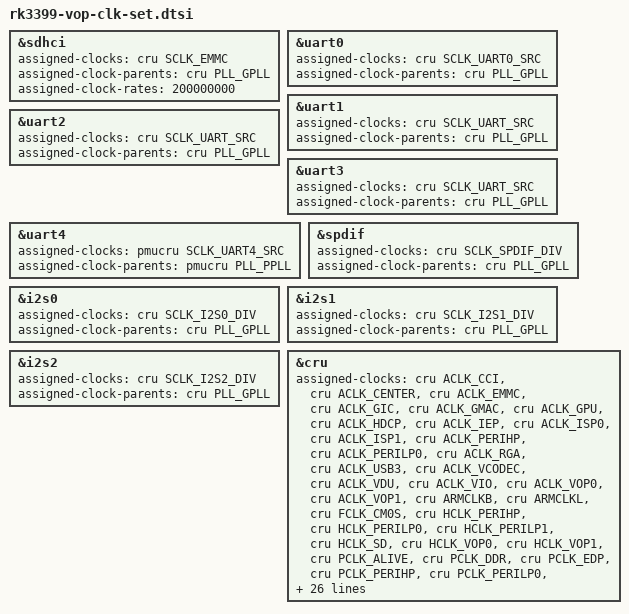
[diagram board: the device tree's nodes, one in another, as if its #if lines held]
/*
 * Copyright (c) 2016 Fuzhou Rockchip Electronics Co., Ltd
 *
 * This file is dual-licensed: you can use it either under the terms
 * of the GPL or the X11 license, at your option. Note that this dual
 * licensing only applies to this file, and not this project as a
 * whole.
 *
 *  a) This file is free software; you can redistribute it and/or
 *     modify it under the terms of the GNU General Public License as
 *     published by the Free Software Foundation; either version 2 of the
 *     License, or (at your option) any later version.
 *
 *     This file is distributed in the hope that it will be useful,
 *     but WITHOUT ANY WARRANTY; without even the implied warranty of
 *     MERCHANTABILITY or FITNESS FOR A PARTICULAR PURPOSE.  See the
 *     GNU General Public License for more details.
 *
 * Or, alternatively,
 *
 *  b) Permission is hereby granted, free of charge, to any person
 *     obtaining a copy of this software and associated documentation
 *     files (the "Software"), to deal in the Software without
 *     restriction, including without limitation the rights to use,
 *     copy, modify, merge, publish, distribute, sublicense, and/or
 *     sell copies of the Software, and to permit persons to whom the
 *     Software is furnished to do so, subject to the following
 *     conditions:
 *
 *     The above copyright notice and this permission notice shall be
 *     included in all copies or substantial portions of the Software.
 *
 *     THE SOFTWARE IS PROVIDED "AS IS", WITHOUT WARRANTY OF ANY KIND,
 *     EXPRESS OR IMPLIED, INCLUDING BUT NOT LIMITED TO THE WARRANTIES
 *     OF MERCHANTABILITY, FITNESS FOR A PARTICULAR PURPOSE AND
 *     NONINFRINGEMENT. IN NO EVENT SHALL THE AUTHORS OR COPYRIGHT
 *     HOLDERS BE LIABLE FOR ANY CLAIM, DAMAGES OR OTHER LIABILITY,
 *     WHETHER IN AN ACTION OF CONTRACT, TORT OR OTHERWISE, ARISING
 *     FROM, OUT OF OR IN CONNECTION WITH THE SOFTWARE OR THE USE OR
 *     OTHER DEALINGS IN THE SOFTWARE.
 */

/*
 * This define is for support double show any dclk frequency.
 * dclk_vop will have a exclusive pll as parent.
 * set dclk_vop will change the pll rate as well.
 */

#ifdef RK3399_TWO_PLL_FOR_VOP

&sdhci {
		assigned-clocks = <&cru SCLK_EMMC>;
		assigned-clock-parents = <&cru PLL_GPLL>;
		assigned-clock-rates = <200000000>;
};

&uart0 {
		assigned-clocks = <&cru SCLK_UART0_SRC>;
		assigned-clock-parents = <&cru PLL_GPLL>;
};

&uart1 {
		assigned-clocks = <&cru SCLK_UART_SRC>;
		assigned-clock-parents = <&cru PLL_GPLL>;
};

&uart2 {
		assigned-clocks = <&cru SCLK_UART_SRC>;
		assigned-clock-parents = <&cru PLL_GPLL>;
};

&uart3 {
		assigned-clocks = <&cru SCLK_UART_SRC>;
		assigned-clock-parents = <&cru PLL_GPLL>;
};

&uart4 {
		assigned-clocks = <&pmucru SCLK_UART4_SRC>;
		assigned-clock-parents = <&pmucru PLL_PPLL>;
};

&spdif {
		assigned-clocks = <&cru SCLK_SPDIF_DIV>;
		assigned-clock-parents = <&cru PLL_GPLL>;
};

&i2s0{
		assigned-clocks = <&cru SCLK_I2S0_DIV>;
		assigned-clock-parents = <&cru PLL_GPLL>;
};

&i2s1 {
		assigned-clocks = <&cru SCLK_I2S1_DIV>;
		assigned-clock-parents = <&cru PLL_GPLL>;
};

&i2s2 {
		assigned-clocks = <&cru SCLK_I2S2_DIV>;
		assigned-clock-parents = <&cru PLL_GPLL>;
};

/* Rockchip had a bunch of duplicate clocks with different rates defined.
 * I have removed the duplicates, using only the one that was assigned last, and put them in alphabetical order.
 * Below are both values for the duplicated clocks for future reference:
 *   ACLK_CCI = 150000000, 600000000
 *   ACLK_CENTER = 100000000, 400000000
 *   ACLK_EMMC = 50000000, 100000000
 *   ACLK_GMAC = 100000000, 400000000
 *   ACLK_PERIHP = 150000000, 75000000
 *   ACLK_PERILP0 = 50000000, 300000000
 *   ACLK_USB3 = 150000000, 300000000
 *   FCLK_CM0S = 50000000, 300000000
 *   HCLK_PERILP1 = 100000000, 50000000
 *   HCLK_SD = 50000000, 200000000
 *   PCLK_ALIVE = 50000000, 100000000
 *   SCLK_CCI_TRACE = 75000000, 150000000
 *   SCLK_CS = 150000000, 75000000
 *   SCLK_RGA_CORE = 400000000
 *   SCLK_VDU_CA = 150000000, 300000000
 */
&cru {
		assigned-clocks =
			 <&cru ACLK_CCI>, <&cru ACLK_CENTER>,
			 <&cru ACLK_EMMC>, <&cru ACLK_GIC>,
			 <&cru ACLK_GMAC>, <&cru ACLK_GPU>,
			 <&cru ACLK_HDCP>, <&cru ACLK_IEP>,
			 <&cru ACLK_ISP0>, <&cru ACLK_ISP1>,
			 <&cru ACLK_PERIHP>, <&cru ACLK_PERILP0>,
			 <&cru ACLK_RGA>, <&cru ACLK_USB3>,
			 <&cru ACLK_VCODEC>, <&cru ACLK_VDU>,
			 <&cru ACLK_VIO>, <&cru ACLK_VOP0>,
			 <&cru ACLK_VOP1>, <&cru ARMCLKB>,
			 <&cru ARMCLKL>, <&cru FCLK_CM0S>,
			 <&cru HCLK_PERIHP>, <&cru HCLK_PERILP0>,
			 <&cru HCLK_PERILP1>, <&cru HCLK_SD>,
			 <&cru HCLK_VOP0>, <&cru HCLK_VOP1>,
			 <&cru PCLK_ALIVE>, <&cru PCLK_DDR>,
			 <&cru PCLK_EDP>, <&cru PCLK_PERIHP>,
			 <&cru PCLK_PERILP0>, <&cru PCLK_PERILP1>,
			 <&cru PLL_GPLL>, <&cru PLL_NPLL>,
			 <&cru SCLK_CCI_TRACE>, <&cru SCLK_CRYPTO0>,
			 <&cru SCLK_CRYPTO1>, <&cru SCLK_CS>,
			 <&cru SCLK_EMMC>, <&cru SCLK_I2C1>,
			 <&cru SCLK_I2C2>, <&cru SCLK_I2C3>,
			 <&cru SCLK_I2C5>, <&cru SCLK_I2C6>,
			 <&cru SCLK_I2C7>, <&cru SCLK_RGA_CORE>,
			 <&cru SCLK_SDMMC>, <&cru SCLK_SPI0>,
			 <&cru SCLK_SPI1>, <&cru SCLK_SPI2>,
			 <&cru SCLK_SPI4>, <&cru SCLK_SPI5>,
			 <&cru SCLK_VDU_CA>, <&cru SCLK_VDU_CORE>,
			 <&cru SCLK_VOP0_PWM>, <&cru SCLK_VOP1_PWM>;
		assigned-clock-rates =
			 /*ACLK_CCI*/ <600000000>,
			 /*ACLK_CENTER*/ <400000000>,
			 /*ACLK_EMMC*/ <100000000>,
			 /*ACLK_GIC*/ <200000000>,
			 /*ACLK_GMAC*/ <400000000>,
			 /*ACLK_GPU*/ <200000000>,
			 /*ACLK_HDCP*/ <400000000>,
			 /*ACLK_IEP*/ <400000000>,
			 /*ACLK_ISP0*/ <400000000>,
			 /*ACLK_ISP1*/ <400000000>,
			 /*ACLK_PERIHP*/ <150000000>,
			 /*ACLK_PERILP0*/ <300000000>,
			 /*ACLK_RGA*/ <400000000>,
			 /*ACLK_USB3*/ <300000000>,
			 /*ACLK_VCODEC*/ <400000000>,
			 /*ACLK_VDU*/ <300000000>,
			 /*ACLK_VIO*/ <400000000>,
			 /*ACLK_VOP0*/ <400000000>,
			 /*ACLK_VOP1*/ <400000000>,
			 /*ARMCLKB*/ <816000000>,
			 /*ARMCLKL*/ <816000000>,
			 /*FCLK_CM0S*/ <300000000>,
			 /*HCLK_PERIHP*/ <75000000>,
			 /*HCLK_PERILP0*/ <100000000>,
			 /*HCLK_PERILP1*/ <100000000>,
			 /*HCLK_SD*/ <200000000>,
			 /*HCLK_VOP0*/ <100000000>,
			 /*HCLK_VOP1*/ <100000000>,
			 /*PCLK_ALIVE*/ <100000000>,
			 /*PCLK_DDR*/ <200000000>,
			 /*PCLK_EDP*/ <100000000>,
			 /*PCLK_PERIHP*/ <37500000>,
			 /*PCLK_PERILP0*/ <50000000>,
			 /*PCLK_PERILP1*/ <50000000>,
			 /*PLL_GPLL*/ <800000000>,
			 /*PLL_NPLL*/ <600000000>,
			 /*SCLK_CCI_TRACE*/ <150000000>,
			 /*SCLK_CRYPTO0*/ <100000000>,
			 /*SCLK_CRYPTO1*/ <200000000>,
			 /*SCLK_CS*/ <150000000>,
			 /*SCLK_EMMC*/ <200000000>,
			 /*SCLK_I2C1*/ <100000000>,
			 /*SCLK_I2C2*/ <100000000>,
			 /*SCLK_I2C3*/ <100000000>,
			 /*SCLK_I2C5*/ <100000000>,
			 /*SCLK_I2C6*/ <100000000>,
			 /*SCLK_I2C7*/ <100000000>,
			 /*SCLK_RGA_CORE*/ <400000000>,
			 /*SCLK_SDMMC*/ <50000000>,
			 /*SCLK_SPI0*/ <50000000>,
			 /*SCLK_SPI1*/ <50000000>,
			 /*SCLK_SPI2*/ <50000000>,
			 /*SCLK_SPI4*/ <50000000>,
			 /*SCLK_SPI5*/ <50000000>,
			 /*SCLK_VDU_CA*/ <300000000>,
			 /*SCLK_VDU_CORE*/ <300000000>,
			 /*SCLK_VOP0_PWM*/ <100000000>,
			 /*SCLK_VOP1_PWM*/ <100000000>;
};
#endif
